VERSION ""

NS_ :

BS_:

BU_: XXX

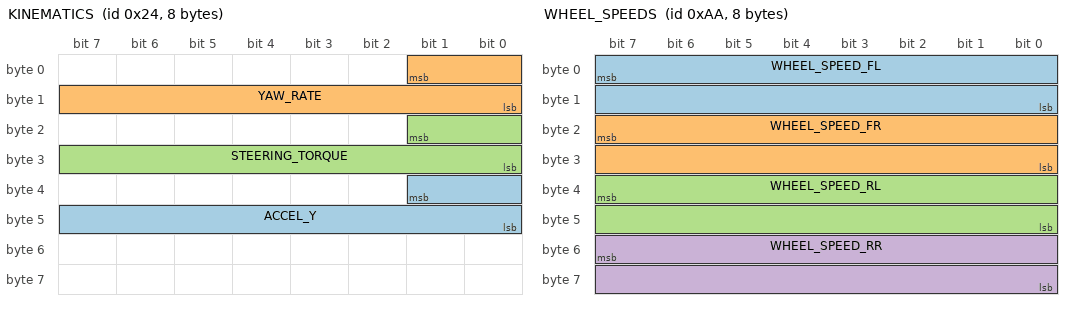
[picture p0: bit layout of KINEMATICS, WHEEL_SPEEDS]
BO_ 36 KINEMATICS: 8 XXX
 SG_ ACCEL_Y : 33|10@0+ (1,-512) [0|65535] "" XXX
 SG_ YAW_RATE : 1|10@0+ (1,-512) [0|65535] "" XXX
 SG_ STEERING_TORQUE : 17|10@0+ (1,-512) [0|65535] "" XXX

BO_ 166 BRAKE: 8 XXX
 SG_ BRAKE_AMOUNT : 7|8@0+ (1,0) [0|255] "" XXX
 SG_ BRAKE_PEDAL : 23|8@0+ (1,0) [0|255] "" XXX

BO_ 170 WHEEL_SPEEDS: 8 XXX
 SG_ WHEEL_SPEED_FL : 7|16@0+ (0.01,-67.67) [0|65535] "kph" XXX
 SG_ WHEEL_SPEED_FR : 23|16@0+ (0.01,-67.67) [0|65535] "kph" XXX
 SG_ WHEEL_SPEED_RL : 39|16@0+ (0.01,-67.67) [0|65535] "kph" XXX
 SG_ WHEEL_SPEED_RR : 55|16@0+ (0.01,-67.67) [0|65535] "kph" XXX

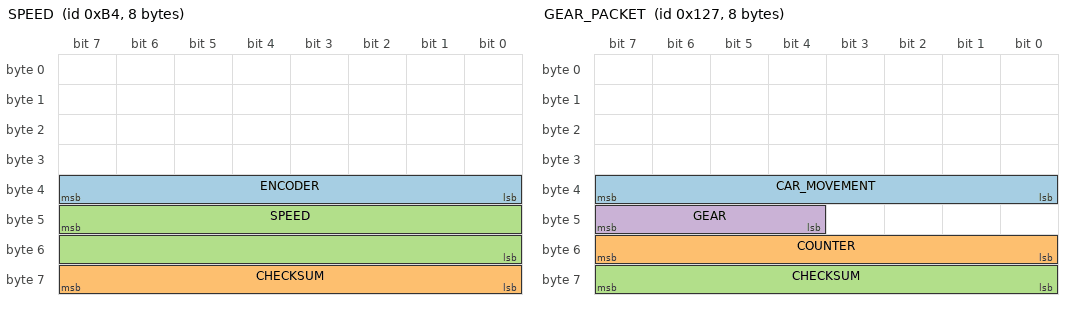
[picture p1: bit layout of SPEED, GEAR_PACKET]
BO_ 180 SPEED: 8 XXX
 SG_ ENCODER : 39|8@0+ (1,0) [0|255] "" XXX
 SG_ CHECKSUM : 63|8@0+ (1,0) [0|255] "" XXX
 SG_ SPEED : 47|16@0+ (1,0) [0|65535] "" XXX

BO_ 295 GEAR_PACKET: 8 XXX
 SG_ CAR_MOVEMENT : 39|8@0- (1,0) [0|255] "" XXX
 SG_ COUNTER : 55|8@0+ (1,0) [0|255] "" XXX
 SG_ CHECKSUM : 63|8@0+ (1,0) [0|255] "" XXX
 SG_ GEAR : 47|4@0+ (1,0) [0|15] "" XXX

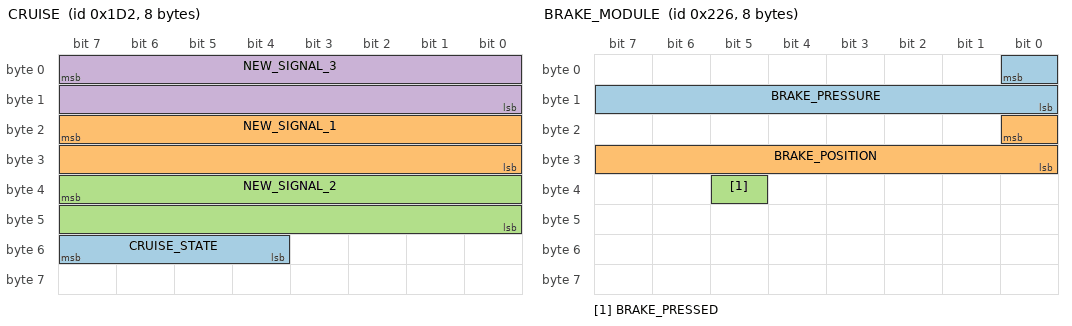
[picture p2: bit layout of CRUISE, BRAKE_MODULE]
BO_ 466 CRUISE: 8 XXX
 SG_ CRUISE_STATE : 55|4@0+ (1,0) [0|15] "" XXX
 SG_ NEW_SIGNAL_1 : 23|16@0- (1,0) [0|65535] "" XXX
 SG_ NEW_SIGNAL_2 : 39|16@0- (1,0) [0|65535] "" XXX
 SG_ NEW_SIGNAL_3 : 7|16@0+ (1,0) [0|65535] "" XXX

BO_ 550 BRAKE_MODULE: 8 XXX
 SG_ BRAKE_PRESSURE : 0|9@0+ (1,0) [0|511] "" XXX
 SG_ BRAKE_POSITION : 16|9@0+ (1,0) [0|511] "" XXX
 SG_ BRAKE_PRESSED : 37|1@0+ (1,0) [0|1] "" XXX

BO_ 552 ACCELEROMETER: 8 XXX
 SG_ ACCEL_Z : 22|15@0- (1,0) [0|32767] "" XXX
 SG_ ACCEL_X : 6|15@0- (1,0) [0|32767] "" XXX

BO_ 560 BRAKE_MODULE2: 8 XXX
 SG_ BRAKE_LIGHTS : 26|1@0+ (1,0) [0|1] "" XXX

BO_ 581 GAS_PEDAL: 8 XXX
 SG_ GAS_PEDAL : 23|8@0+ (0.005,0) [0|1] "" XXX

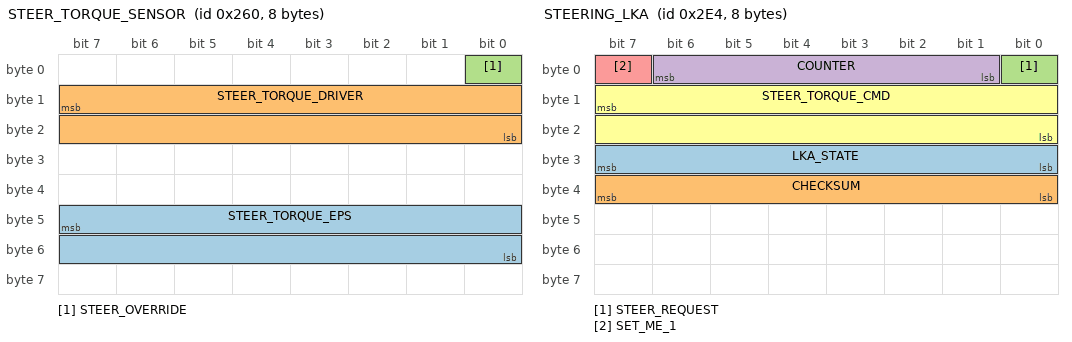
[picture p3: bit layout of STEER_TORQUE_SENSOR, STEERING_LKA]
BO_ 608 STEER_TORQUE_SENSOR: 8 XXX
 SG_ STEER_TORQUE_EPS : 47|16@0- (0.5,0) [0|65535] "" XXX
 SG_ STEER_TORQUE_DRIVER : 15|16@0- (1,0) [-32768|32767] "" XXX
 SG_ STEER_OVERRIDE : 0|1@0+ (1,0) [0|1] "" XXX

BO_ 614 STEERING_IPAS: 8 XXX
 SG_ FLAG : 7|4@0+ (1,0) [0|15] "" XXX
 SG_ ANGLE : 3|12@0- (1,0) [0|16777215] "" XXX

BO_ 643 PRE_COLLISION: 8 XXX

BO_ 740 STEERING_LKA: 8 XXX
 SG_ LKA_STATE : 31|8@0+ (1,0) [0|255] "" XXX
 SG_ CHECKSUM : 39|8@0+ (1,0) [0|255] "" XXX
 SG_ STEER_REQUEST : 0|1@0+ (1,0) [0|1] "" XXX
 SG_ COUNTER : 6|6@0+ (1,0) [0|63] "" XXX
 SG_ SET_ME_1 : 7|1@0+ (1,0) [0|1] "" XXX
 SG_ STEER_TORQUE_CMD : 15|16@0- (1,0) [0|65535] "" XXX

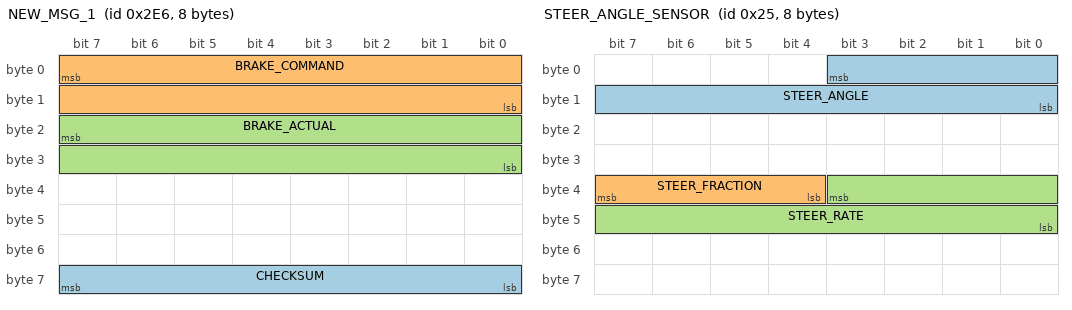
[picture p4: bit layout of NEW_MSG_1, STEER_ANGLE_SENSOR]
BO_ 742 NEW_MSG_1: 8 XXX
 SG_ CHECKSUM : 63|8@0+ (1,0) [0|255] "" XXX
 SG_ BRAKE_COMMAND : 7|16@0- (1,0) [0|65535] "" XXX
 SG_ BRAKE_ACTUAL : 23|16@0- (1,0) [0|65535] "" XXX

BO_ 1556 STEERING_LEVERS: 8 XXX
 SG_ TURN_SIGNALS : 29|2@0+ (1,0) [0|3] "" XXX

BO_ 37 STEER_ANGLE_SENSOR: 8 XXX
 SG_ STEER_ANGLE : 3|12@0- (1.5,0) [-500|500] "deg" XXX
 SG_ STEER_FRACTION : 39|4@0- (0.1,0) [-0.7|0.7] "deg" XXX
 SG_ STEER_RATE : 35|12@0- (1,0) [-2000|2000] "deg/s" XXX

BO_ 467 CRUISE_2: 8 XXX
 SG_ MAIN_ON : 15|1@0+ (1,0) [0|1] "" XXX
 SG_ SET_SPEED : 23|8@0+ (1,0) [0|255] "kph" XXX

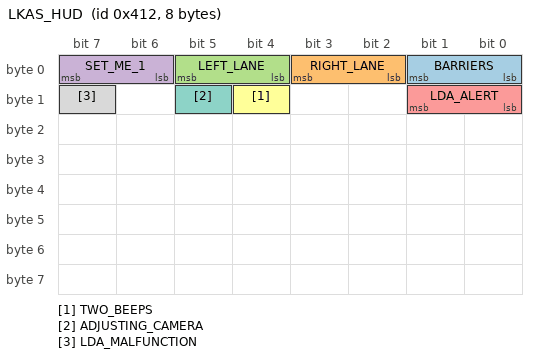
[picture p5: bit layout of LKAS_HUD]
BO_ 1042 LKAS_HUD: 8 XXX
 SG_ BARRIERS : 1|2@0+ (1,0) [0|3] "" XXX
 SG_ RIGHT_LANE : 3|2@0+ (1,0) [0|3] "" XXX
 SG_ LEFT_LANE : 5|2@0+ (1,0) [0|3] "" XXX
 SG_ SET_ME_1 : 7|2@0+ (1,0) [0|3] "" XXX
 SG_ LDA_ALERT : 9|2@0+ (1,0) [0|3] "" XXX
 SG_ TWO_BEEPS : 12|1@0+ (1,0) [0|1] "" XXX
 SG_ ADJUSTING_CAMERA : 13|1@0+ (1,0) [0|1] "" XXX
 SG_ LDA_MALFUNCTION : 15|1@0+ (1,0) [0|1] "" XXX

CM_ SG_ 36 ACCEL_Y "unit is tbd";
CM_ SG_ 36 YAW_RATE "verify";
CM_ SG_ 36 STEERING_TORQUE "does not seem the steer torque, tbd";
CM_ SG_ 550 BRAKE_PRESSURE "seems prop to pedal force";
CM_ SG_ 550 BRAKE_POSITION "seems proportional to pedal displacement, unclear the max value of 0x1c8";
CM_ SG_ 560 BRAKE_LIGHTS "double check";
CM_ SG_ 581 GAS_PEDAL "it seems slightly filtered";
CM_ SG_ 608 STEER_TORQUE_EPS "0.5 factor to be comparable with STEER_TORQUE_CMD";
CM_ SG_ 608 STEER_TORQUE_DRIVER "driver torque";
CM_ SG_ 608 STEER_OVERRIDE "set when driver torque exceeds a certain value";
CM_ SG_ 37 STEER_FRACTION "1/15th of the signal STEER_ANGLE, which is 1.5 deg; note that 0x8 is never set";
CM_ SG_ 37 STEER_RATE "factor is tbd";
CM_ SG_ 467 SET_SPEED "43 kph are shown as 28mph, so conversion isnt perfect";
CM_ SG_ 1042 SET_ME_1 "unclear what this is, nut it's always 1 in drive traces";
VAL_ 466 CRUISE_STATE 8 "active" 7 "standstill" 1 "off" ;
VAL_ 1556 TURN_SIGNALS 3 "none" 2 "right" 1 "left" ;
VAL_ 1042 BARRIERS 3 "both" 2 "right" 1 "left" 0 "none" ;
VAL_ 1042 LDA_ALERT 3 "hold with continuous beep" 2 "LDA unavailable" 1 "hold" 0 "none" ;
